# A31L22x register map
Vendor: VENDOR ABOV Semiconductor Co., Ltd.; Series: A31L22x; File version: 1.0
CPU: CM0+ r0p1, little endian, no MPU, no FPU, VTOR, 2 interrupt priority bits
Registers are 32-bit, read-write, reset 0x0 unless marked. A register's access mark holds for its fields unless they carry their own. Offsets are from the block's base; [hi:lo] are bit positions; {n}, {i} and the like mark numbered series; 'fields as' and 'values as' point back to an identical list.

## PMU — Power Management Unit
Base 0x40001900
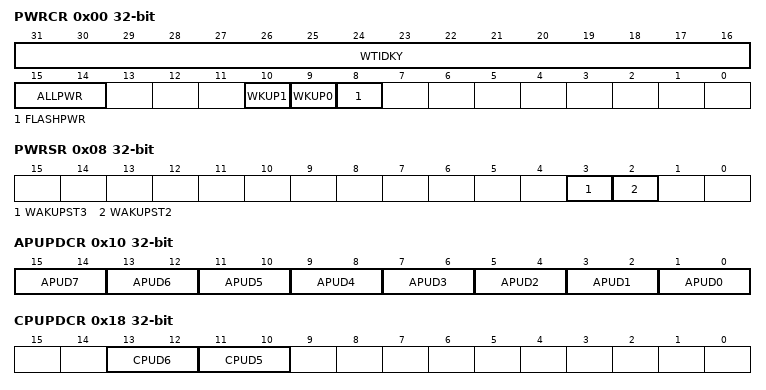
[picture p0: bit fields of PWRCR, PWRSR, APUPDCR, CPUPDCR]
0x00 PWRCR — Power Management Control Register
  [31:16] WTIDKY wo — Write Identification Key (0x5A3C)
    0x5A3C=Value (Key Value (0x5A3C))
  [15:14] ALLPWR — All System and Peripheral Except Always-on Region Power Control
    0=Deep sleep mode 0, can be waked-up by optional and enabled peripherals; 2=Deep sleep mode 2, can be waked-up by optional peripherals and wakeup pins; 3=Deep sleep mode 3 (Shutdown), can be waked-up by T60 and wakeup pins
  [10] WKUP1 — Wake-Up function control bit (when the ALLPWR bits are not '00b'), PA2
    0=Disable wake-up function from deep sleep mode; 1=Enable wake-up function from deep sleep mode
  [9] WKUP0 — Wake-Up function control bit (when the ALLPWR bits are not '00b'), PA0
    values as WKUP1
  [8] FLASHPWR — Flash Memory Power Control
    0=On (Power On); 1=Off (Power Off)
0x08 PWRSR — Power Management Status Register
  [3] WAKUPST3 — Wake-up Reset Status 3 bit. A system reset will occur and this bit is set when the system wakes up from deep sleep mode 3 (PMU_PWRCR.ALLPWR = 3, Shutdown).
    0=NotDetected; 1=Detected (Wake-up reset is detected, This bit is cleared to '0' when write '1'.)
  [2] WAKUPST2 — Wake-up Reset Status 2 bit. A core reset will occur and this bit is set when the system wakes up from deep sleep mode 2 (PMU_PWRCR.ALLPWR = 2).
    values as WAKUPST3
0x10 APUPDCR — Power Port A Pull-up/down Control Register
  [all] fields
    0=DisablePUDR (Disable the pull-up/down resistors.); 1=EnablePUR (Enable the pull-up resistor.); 2=EnablePDR (Enable the pull-down resistor.)
  [2n+1:2n] APUD{n} (n=0..7) — Pull-up/down control bits (when the ALLPWR bits are not '00b')
0x18 CPUPDCR — Power Port C Pull-up/down Control Register
  [13:12] CPUD6 — Pull-up/down control bits (when the ALLPWR bits are not '00b')
    values as the fields of APUPDCR
  [11:10] CPUD5 — Pull-up/down control bits (when the ALLPWR bits are not '00b')
    values as the fields of APUPDCR
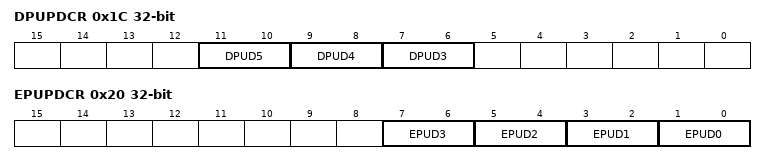
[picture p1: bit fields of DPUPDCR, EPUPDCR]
0x1C DPUPDCR — Power Port D Pull-up/down Control Register
  [all] fields
    values as the fields of APUPDCR
  [11:10] DPUD5 — Pull-up/down control bits (when the ALLPWR bits are not '00b')
  [9:8] DPUD4 — Pull-up/down control bits (when the ALLPWR bits are not '00b')
  [7:6] DPUD3 — Pull-up/down control bits (when the ALLPWR bits are not '00b')
0x20 EPUPDCR — Power Port E Pull-up/down Control Register
  [all] fields
    values as the fields of APUPDCR
  [2n+1:2n] EPUD{n} (n=0..3) — Pull-up/down control bits (when the ALLPWR bits are not '00b')
{0x40+i} BKR{i} 8-bit (i=0..31) — Back-up Data Register {i}
  [7:0] BACKUP — Back-up Data

## ADC — High Speed 12 Bit A/D Converter
Base 0x40003000
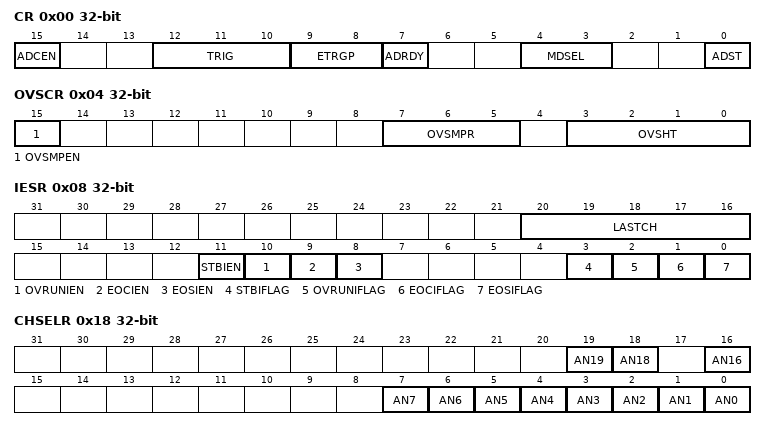
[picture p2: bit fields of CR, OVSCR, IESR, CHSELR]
0x00 CR — A/D Converter Control Register
  [15] ADCEN — ADC Module Enable
    0=Disable ADC Module Operation; 1=Enable ADC Module Operation
  [12:10] TRIG — ADC Trigger Signal Selection
    0=ADST (Select ADST.); {v}=TIMER{v+39} (Timer {v+39} Trigger Signals) (v=1..4); 7=ADTRG (External ADC Trigger Input)
  [9:8] ETRGP — ADC External Trigger Input Polarity Selection
    0=Disable ADC external trigger function; 1=FallingEdge (Trigger on falling edge); 2=RisingEdge (Trigger on rising edge); 3=BothEdge (Trigger on both of falling and rising edge)
  [7] ADRDY — ADC Conversion Ready
    0=Stop subsequent steps; 1=Ready to convert
  [4:3] MDSEL — ADC Conversion Mode Selection
    0=Single Conversion Mode; 1=Sequential Conversion Mode; 2=Continuous Conversion Mode
  [0] ADST — ADC Conversion Start
    0=NoEffect; 1=Start (Trigger signal generation for conversion start.)
0x04 OVSCR — A/D Converter Oversampling Control Register
  [15] OVSMPEN — Oversampling Enable
    0=Disable oversampling; 1=Enable oversampling
  [7:5] OVSMPR — Oversampling Ratio Selection
  [3:0] OVSHT — Oversampling Data Shift
    0=NoShift; {v}=ShiftRight{v}Bit (v=1..8)
0x08 IESR — A/D Converter Interrupt Enable and Status Register
  [20:16] LASTCH ro — ADC Last Conversion Channel Numbe
  [11] STBIEN — ADC Stabilization Interrupt Enable
    0=Disable stabilization interrupt; 1=Enable stabilization interrupt
  [10] OVRUNIEN — ADC Data Overrun Interrupt Enable
    0=Disable overrun interrupt; 1=Enable overrun interrupt
  [9] EOCIEN — ADC End of Conversion Interrupt Enable
    0=Disable end of conversion interrupt; 1=Enable end of conversion interrupt
  [8] EOSIEN — ADC End of Sequence Interrupt Enable
    0=Disable end of sequence interrupt; 1=Enable end of sequence interrupt
  [3] STBIFLAG — ADC Stabilization Interrupt Flag
    0=No request occurred; 1=Request occurred
  [2] OVRUNIFLAG — ADC Data Overrun Interrupt Flag
    0=No request occurred; 1=Request occurred
  [1] EOCIFLAG — ADC End of Conversion Interrupt Flag
    0=No request occurred; 1=Request occurred
  [0] EOSIFLAG — ADC End of Sequence Interrupt Flag
    0=No request occurred; 1=Request occurred
0x0C DR ro (reset mask 0xFFFF0000) — A/D Converter Data Register
  [15:0] ADDATA — A/D Converter Result Data
0x10 PREDR — A/D Converter Prescaler Data Register
  [3:0] PRED — A/D Converter Prescaler Data
0x14 SAMR — A/D Converter Sampling Time Register
  [4:0] SAMCK — Sampling Cycles for Sample/Hold Circuit
0x18 CHSELR — A/D Converter Channel Selection Register
  [all] fields
    0=NotSelected (ANx is not selected for conversion); 1=Selected (ANx is selected for conversion)
  [19] AN19 — AN19(BGR) Channel Selection
  [18] AN18 — AN18(VDD) Channel Selection
  [16] AN16 — AN16(VSS) Channel Selection
  [n] AN{n} (n=0..7) — AN{n} Channel Selection
